# 3061MNNICA register map
File version: 1.0
Registers are 32-bit, access per field, reset 0x0 unless marked. A register's access mark holds for its fields unless they carry their own. Offsets are from the block's base; [hi:lo] are bit positions; {n}, {i} and the like mark numbered series.

## MTIMER — MTIMER peripheral interface
Base 0x14380000
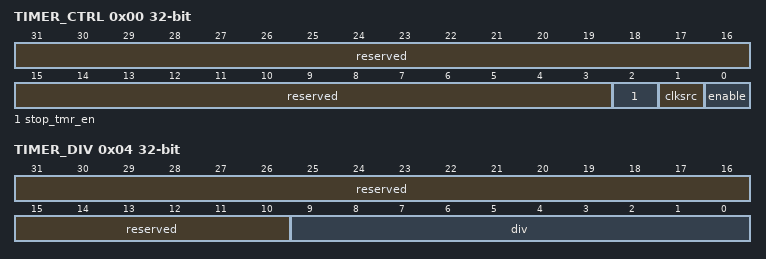
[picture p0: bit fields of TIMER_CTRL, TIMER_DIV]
0x00 TIMER_CTRL — Mtimer控制寄存器。
  [31:3] reserved ro — 保留。
  [2] stop_tmr_en rw — 调试模式停止计数控制。 0：调试模式下定时间继续计数； 1：调试模式下定时器停止计数。
  [1] clksrc rw — Mtimer时钟源选择。 0：使用主时钟（处理器时钟）； 1：保留。
  [0] enable rw — Mtimer使能。 0：Mtimer不使能； 1：Mtimer使能，当计数值大于等于比较值时会上报中断。
0x04 TIMER_DIV — Mtimer分频寄存器。
  [31:10] reserved ro — 保留。
  [9:0] div rw — 定时器分频控制，每div+1个计时时钟周期会让计数寄存器加1。
0x08 MTIME rw — Mtimer计数值低32bit寄存器。
  [31:0] mtime — Mtimer计数寄存器低32bit。
0x0C MTIME_H rw — Mtimer计数值高32bit寄存器。
  [31:0] mtime_h — Mtimer计数寄存器高32bit，当计数器低32bit溢出时加1。
0x10 MTIMECMP rw — Mtimer比较值低32bit寄存器。
  [31:0] mtimecmp — Mtimer比较寄存器低32bit，写入任意值会清除中断状态。
0x14 MTIMECMP_H rw — Mtimer比较值高32bit寄存器。
  [31:0] mtimecmp_h — Mtimer比较寄存器高32bit，写入任意值会清除中断状态。

## PGA0 — PGA peripheral interface
Base 0x18200000
Same registers: PGA1 0x18201000
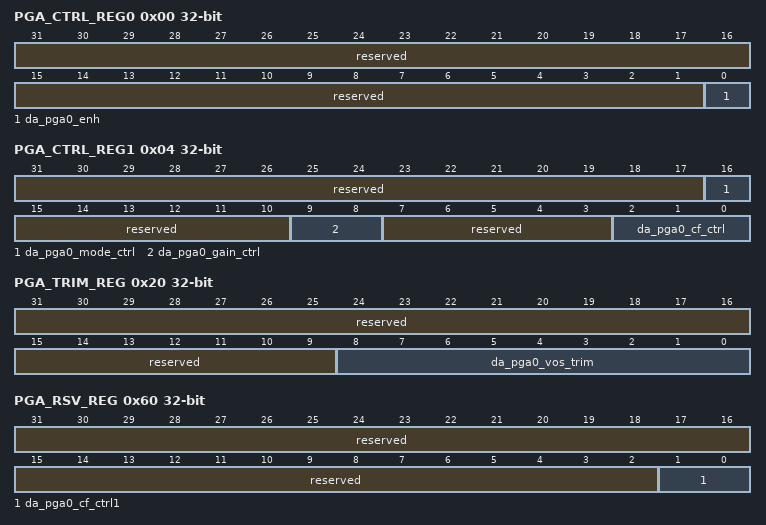
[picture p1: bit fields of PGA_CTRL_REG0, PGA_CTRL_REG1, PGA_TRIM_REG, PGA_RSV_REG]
0x00 PGA_CTRL_REG0 — PGA控制寄存器0。
  [31:1] reserved ro — 保留。
  [0] da_pga0_enh rw — PGA使能信号： 0:关闭; 1:使能。
0x04 PGA_CTRL_REG1 — PGA控制寄存器1。
  [31:17] reserved ro — 保留。
  [16] da_pga0_mode_ctrl rw — PGA模式配置： 0：内部电阻增益模式； 1：外部电阻增益模式。
  [15:10] reserved ro — 保留。
  [9:8] da_pga0_gain_ctrl rw — PGA内部电阻增益配置： 00：x2； 01：x4； 10：x8； 11：x16。
  [7:3] reserved ro — 保留。
  [2:0] da_pga0_cf_ctrl rw — PGA外部增益模式下的前馈电容补偿配置： 000：x2； 001：x3； 010：x4； 011：x5； 100：x6； 101：x7； 110：x8； 111：x9。
0x20 PGA_TRIM_REG — PGA TRIM寄存器。
  [31:9] reserved ro — 保留。
  [8:0] da_pga0_vos_trim rw — PGA的失调trim信息。
0x60 PGA_RSV_REG — PGA预留寄存器。
  [31:2] reserved ro — 保留。
  [1:0] da_pga0_cf_ctrl1 rw — 外部增益模式下的前馈电容补偿配置。 00：保留； 01：x10-x12； 10：x13-x15； 11：x16-x20。 注意：配置时需要将da_pga0_cf_ctrl配置为111。

## PMC — PMC peripheral interface
Base 0x147E0000
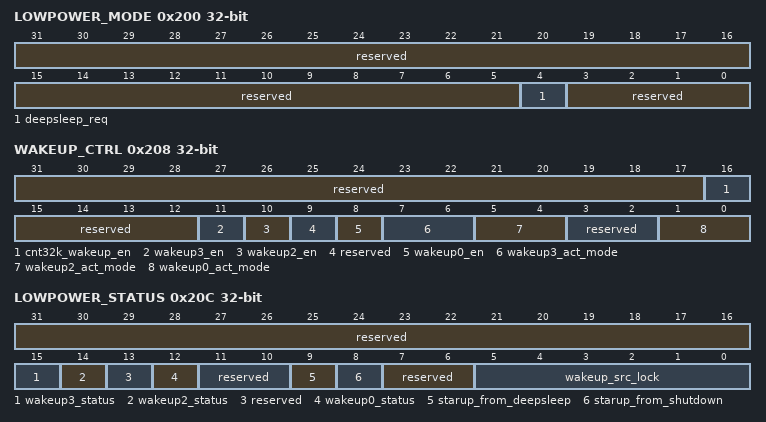
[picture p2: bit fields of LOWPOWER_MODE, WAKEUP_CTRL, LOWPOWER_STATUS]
0x200 LOWPOWER_MODE — 低功耗模式控制寄存器。
  [31:5] reserved ro — 保留。
  [4] deepsleep_req wo — 系统进入deepsleep模式请求。 对此寄存器位域写1操作将触发芯片进入deepsleep模式流程。
  [3:0] reserved ro — 保留。
0x204 CNT32K_WAKE_CYC rw reset 0xFFFF — 定时唤醒周期设置寄存器。
  [31:0] cnt32k_wakeup_cycle — 定时唤醒周期数（计数时钟clk_losc）。
0x208 WAKEUP_CTRL — deepsleep模式唤醒控制寄存器。
  [31:17] reserved ro — 保留。
  [16] cnt32k_wakeup_en rw — 定时唤醒使能。 0：不使能； 1：使能。
  [15:12] reserved ro — 保留。
  [11] wakeup3_en rw — WAKEUP3使能。 0：不使能； 1：使能。
  [10] wakeup2_en rw — WAKEUP2使能。 0：不使能； 1：使能。
  [9] reserved ro — 保留。
  [8] wakeup0_en rw — WAKEUP0使能。 0：不使能； 1：使能。
  [7:6] wakeup3_act_mode rw — WAKEUP3有效模式选择。 00：上升沿有效； 01：下降沿有效； 10：高电平有效； 11：低电平有效。
  [5:4] wakeup2_act_mode rw — WAKEUP2有效模式选择。 00：上升沿有效； 01：下降沿有效； 10：高电平有效； 11：低电平有效。
  [3:2] reserved ro — 保留。
  [1:0] wakeup0_act_mode rw — WAKEUP0有效模式选择。 00：上升沿有效； 01：下降沿有效； 10：高电平有效； 11：低电平有效。
0x20C LOWPOWER_STATUS ro — 低功耗状态查询寄存器。
  [31:16] reserved — 保留。
  [15] wakeup3_status — wakeup3唤醒源状态。 0：唤醒源低电平； 1：唤醒源高电平。
  [14] wakeup2_status — wakeup2唤醒源状态。 0：唤醒源低电平； 1：唤醒源高电平。
  [13] reserved — 保留。
  [12] wakeup0_status — wakeup0唤醒源状态。 0：唤醒源低电平； 1：唤醒源高电平。
  [11:10] reserved — 保留。
  [9] starup_from_deepsleep — 从deepsleep状态启动标识。 0：未从deepsleep模式启动； 1：从deepsleep模式启动。
  [8] starup_from_shutdown — 芯片初次上电启动标识。 0：不是初次上电启动； 1：是初次上电启动。
  [7:6] reserved — 保留。
  [5:0] wakeup_src_lock — 启动唤醒源查询。 bit[5]：RESETN管脚唤醒； bit[4]：WAKEUP3唤醒； bit[3]：WAKEUP2唤醒； bit[2]：WAKEUP1唤醒； bit[1]：WAKEUP0唤醒； bit[0]：cnt32k定时唤醒。
{0xF00+4i} AON_USER_REG{i} rw (i=0..3) — AON域用户寄存器{i}。
  [31:0] aon_user_reg{i} — AON电源域通用寄存器{i}。

## SYSCTRL0 — SYSCTRL0_REG peripheral interface
Base 0x10100000
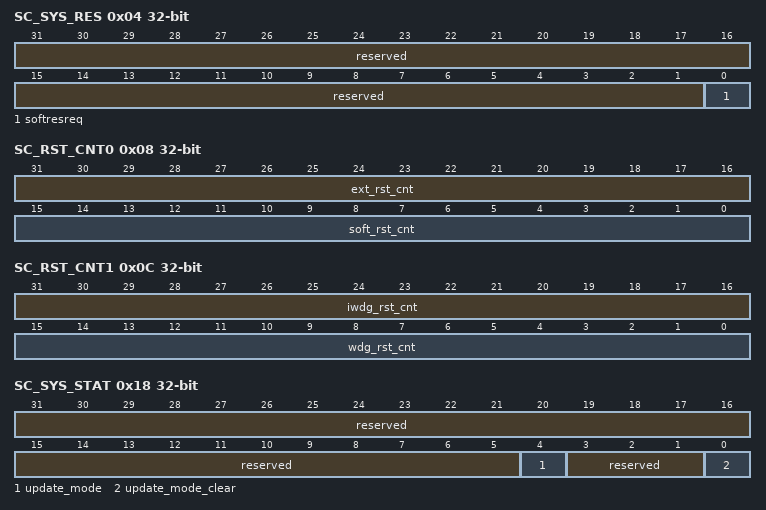
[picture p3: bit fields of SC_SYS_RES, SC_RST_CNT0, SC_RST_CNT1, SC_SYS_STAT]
0x04 SC_SYS_RES — 系统软件复位寄存器。
  [31:1] reserved ro — 保留。
  [0] softresreq rw — 对此寄存器位域的任意写操作都会导致系统软复位。
0x08 SC_RST_CNT0 ro — 复位次数统计寄存器0。
  [31:16] ext_rst_cnt — RESETN管脚复位次数统计。
  [15:0] soft_rst_cnt — 软复位次数统计。
0x0C SC_RST_CNT1 ro — 复位次数统计寄存器1。
  [31:16] iwdg_rst_cnt — iwdg复位次数统计。
  [15:0] wdg_rst_cnt — wdg复位次数统计。
0x18 SC_SYS_STAT — 系统启动模式寄存器。
  [31:5] reserved ro — 保留。
  [4] update_mode ro — 系统升级标识，芯片上电时锁存。 0：不升级，直接启动模式； 1：升级模式。 注：当处于升级模式时，芯片JTAG相关管脚强制为JTAG功能，无法软件切换为其他复用功能。
  [3:1] reserved ro — 保留。
  [0] update_mode_clear rw — 系统升级标识清除寄存器，芯片上电完成后生效。 0：不清除； 1：清除。
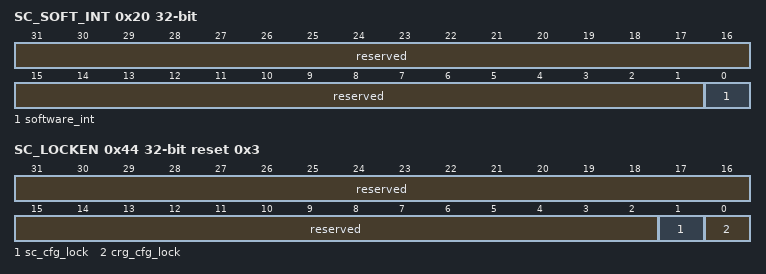
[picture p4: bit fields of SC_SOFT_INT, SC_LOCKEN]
0x20 SC_SOFT_INT — 软件中断寄存器。
  [31:1] reserved ro — 保留。
  [0] software_int rw — 软件中断寄存器。 0：清除中断； 1：产生中断。
0x24 SC_SOFT_EVT_ID rw — 软中断事件ID寄存器。
  [31:0] swint_evt_id — 软中断事件ID，可用于软中断事件类型定义。
0x44 SC_LOCKEN reset 0x3 — 关键寄存器的写保护控制寄存器。
  [31:2] reserved ro — 保留。
  [1] sc_cfg_lock rw — SYSCTRL相关寄存器写保护。 0：写使能； 1：写禁止。
  [0] crg_cfg_lock rw — CRG相关寄存器写保护。 0：写使能； 1：写禁止。
0x200 SC_HRST_REG0 rw — SC专用硬复位寄存器0。
  [31:0] sc_hrst_reg0 — 系统正常启动流程中，如果检测到此寄存器值为0xA5A5A5A5，则CPU将停止启动系统，此时可以通过JTAG/SWD接口调试（或烧写）。
0xE00 USER_POR_REG0 rw — USER专用POR复位寄存器0。
  [31:0] user_por_reg0 — USER专用REG0。
0xE04 USER_POR_REG1 rw — USER专用POR复位寄存器1。
  [31:0] user_por_reg1 — USER专用REG1。
0xE40 USER_HRST_REG0 rw — USER专用硬复位寄存器0。
  [31:0] user_hrst_reg0 — USER专用REG2。
0xE44 USER_HRST_REG1 rw — USER专用硬复位寄存器1。
  [31:0] user_hrst_reg1 — USER专用REG3。
0xE80 USER_REG0 rw — USER专用寄存器0。
  [31:0] user_reg0 — USER专用REG4。
0xE84 USER_REG1 rw — USER专用寄存器1。
  [31:0] user_reg1 — USER专用REG5。
